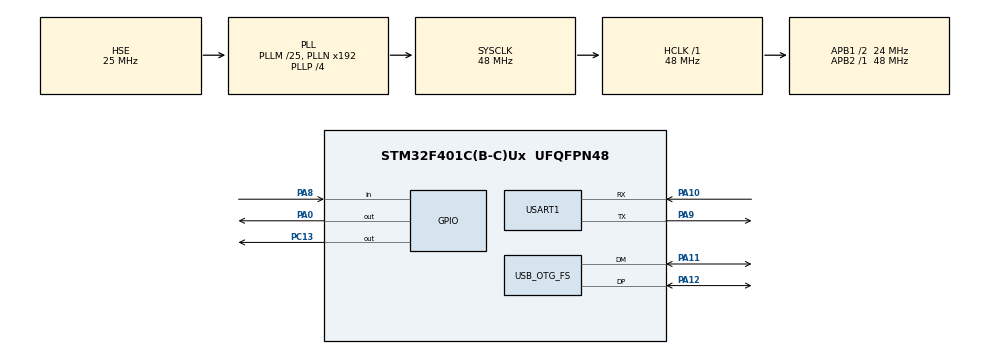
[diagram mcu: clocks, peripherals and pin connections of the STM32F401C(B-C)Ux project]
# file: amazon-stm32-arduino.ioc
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Mcu.Family=STM32F4
Mcu.Name=STM32F401C(B-C)Ux
Mcu.Package=UFQFPN48
NVIC.OTG_FS_IRQn=true\:0\:0\:false\:false\:true\:false\:true\:true
NVIC.PriorityGroup=NVIC_PRIORITYGROUP_4
PA0-WKUP.Signal=GPIO_Output
PA10.Mode=Asynchronous
PA10.Signal=USART1_RX
PA11.Mode=Device_Only
PA11.Signal=USB_OTG_FS_DM
PA12.Mode=Device_Only
PA12.Signal=USB_OTG_FS_DP
PA8.GPIO_PuPd=GPIO_PULLUP
PA8.Signal=GPIO_Input
PA9.Mode=Asynchronous
PA9.Signal=USART1_TX
PC13-ANTI_TAMP.Signal=GPIO_Output
PH0\ -\ OSC_IN.Mode=HSE-External-Oscillator
PH0\ -\ OSC_IN.Signal=RCC_OSC_IN
PH1\ -\ OSC_OUT.Mode=HSE-External-Oscillator
PH1\ -\ OSC_OUT.Signal=RCC_OSC_OUT
ProjectManager.HeapSize=0x200
ProjectManager.StackSize=0x400
ProjectManager.TargetToolchain=STM32CubeIDE
RCC.48MHZClocksFreq_Value=48000000
RCC.AHBFreq_Value=48000000
RCC.APB1CLKDivider=RCC_HCLK_DIV2
RCC.APB1Freq_Value=24000000
RCC.APB1TimFreq_Value=48000000
RCC.APB2Freq_Value=48000000
RCC.APB2TimFreq_Value=48000000
RCC.CortexFreq_Value=48000000
RCC.HCLKFreq_Value=48000000
RCC.HSE_VALUE=25000000
RCC.HSI_VALUE=16000000
RCC.LSE_VALUE=32768
RCC.PLLM=25
RCC.PLLP=RCC_PLLP_DIV4
RCC.SYSCLKFreq_VALUE=48000000
RCC.SYSCLKSource=RCC_SYSCLKSOURCE_PLLCLK
RCC.VCOOutputFreq_Value=192000000
USART1.VirtualMode=VM_ASYNC
USB_DEVICE.CLASS_NAME_FS=CDC
USB_DEVICE.VirtualMode=Cdc
USB_DEVICE.VirtualModeFS=Cdc_FS
USB_OTG_FS.VirtualMode=Device_Only
VP_USB_DEVICE_VS_USB_DEVICE_CDC_FS.Mode=CDC_FS
board=custom

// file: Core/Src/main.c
/* USER CODE BEGIN Header */
/**
 ******************************************************************************
 * @file           : main.c
 * @brief          : Main program body
 ******************************************************************************
 * @attention
 *
 * <h2><center>&copy; Copyright (c) 2022 STMicroelectronics.
 * All rights reserved.</center></h2>
 *
 * This software component is licensed by ST under BSD 3-Clause license,
 * the "License"; You may not use this file except in compliance with the
 * License. You may obtain a copy of the License at:
 *                        opensource.org/licenses/BSD-3-Clause
 *
 ******************************************************************************
 */
/* USER CODE END Header */
#include "main.h"
#include "usart.h"
#include "usb_device.h"
#include "gpio.h"

/* USER CODE BEGIN Includes */
#include <stdbool.h>
/* USER CODE END Includes */

void SystemClock_Config(void);

/* USER CODE BEGIN 0 */

// Defined deep within STM32 driver code, but we yank it out here
extern USBD_HandleTypeDef hUsbDeviceFS;

#include "usbd_cdc_if.h"

// Overwrite _write so printf prints to USB
int _write(int file, char *ptr, int len) {
  // Check here to make sure that USB things are actually set up
  if (hUsbDeviceFS.dev_state != USBD_STATE_CONFIGURED) return 0;

  // Try to send -- CDC_Transmit_FS is what actually sends our data
  if (USBD_OK == CDC_Transmit_FS((uint8_t *)ptr, len)) return len;

  // Failure, report sending zero bytes
  return 0;
}
/* USER CODE END 0 */

int main(void)
{

  /* MCU Configuration--------------------------------------------------------*/

  /* Reset of all peripherals, Initializes the Flash interface and the Systick. */
  HAL_Init();

  /* Configure the system clock */
  SystemClock_Config();

  /* Initialize all configured peripherals */
  MX_GPIO_Init();
  MX_USB_DEVICE_Init();
  MX_USART1_UART_Init();

  /* Infinite loop */
  /* USER CODE BEGIN WHILE */
  while (1) {
    //    bool buttonState = HAL_GPIO_ReadPin(GPIOC, GPIO_PIN_4);
    //    if (buttonState) {
    //      HAL_GPIO_WritePin(GPIOA, GPIO_PIN_1, GPIO_PIN_SET);
    //    } else {
    //      HAL_GPIO_WritePin(GPIOA, GPIO_PIN_1, GPIO_PIN_RESET);
    //    }

    // We want to turn pin PA0 (same as on breadboard) "ON"
    // to turn LED on
    // On == Set, Off = Reset
    HAL_GPIO_WritePin(GPIOC, GPIO_PIN_13, GPIO_PIN_SET);

    // Wait half a second (or 500ms
    HAL_Delay(500);

    // Turn LED back off
    HAL_GPIO_WritePin(GPIOC, GPIO_PIN_13, GPIO_PIN_RESET);

    // And wait a bit
    HAL_Delay(500);

    /* USER CODE END WHILE */

  }
}

void SystemClock_Config(void)
{
  RCC_OscInitTypeDef RCC_OscInitStruct = {0};
  RCC_ClkInitTypeDef RCC_ClkInitStruct = {0};

  /** Configure the main internal regulator output voltage
  */
  __HAL_RCC_PWR_CLK_ENABLE();
  __HAL_PWR_VOLTAGESCALING_CONFIG(PWR_REGULATOR_VOLTAGE_SCALE2);
  /** Initializes the RCC Oscillators according to the specified parameters
  * in the RCC_OscInitTypeDef structure.
  */
  RCC_OscInitStruct.OscillatorType = RCC_OSCILLATORTYPE_HSE;
  RCC_OscInitStruct.HSEState = RCC_HSE_ON;
  RCC_OscInitStruct.PLL.PLLState = RCC_PLL_ON;
  RCC_OscInitStruct.PLL.PLLSource = RCC_PLLSOURCE_HSE;
  RCC_OscInitStruct.PLL.PLLM = 25;
  RCC_OscInitStruct.PLL.PLLN = 192;
  RCC_OscInitStruct.PLL.PLLP = RCC_PLLP_DIV4;
  RCC_OscInitStruct.PLL.PLLQ = 4;
  if (HAL_RCC_OscConfig(&RCC_OscInitStruct) != HAL_OK)
  {
    Error_Handler();
  }
  /** Initializes the CPU, AHB and APB buses clocks
  */
  RCC_ClkInitStruct.ClockType = RCC_CLOCKTYPE_HCLK|RCC_CLOCKTYPE_SYSCLK
                              |RCC_CLOCKTYPE_PCLK1|RCC_CLOCKTYPE_PCLK2;
  RCC_ClkInitStruct.SYSCLKSource = RCC_SYSCLKSOURCE_PLLCLK;
  RCC_ClkInitStruct.AHBCLKDivider = RCC_SYSCLK_DIV1;
  RCC_ClkInitStruct.APB1CLKDivider = RCC_HCLK_DIV2;
  RCC_ClkInitStruct.APB2CLKDivider = RCC_HCLK_DIV1;

  if (HAL_RCC_ClockConfig(&RCC_ClkInitStruct, FLASH_LATENCY_1) != HAL_OK)
  {
    Error_Handler();
  }
}

void Error_Handler(void)
{
  __disable_irq();
  while (1) {
  }
}

#ifdef  USE_FULL_ASSERT
/**
  * @brief  Reports the name of the source file and the source line number
  *         where the assert_param error has occurred.
  * @param  file: pointer to the source file name
  * @param  line: assert_param error line source number
  * @retval None
  */
void assert_failed(uint8_t *file, uint32_t line)
{
  /* USER CODE BEGIN 6 */
  /* User can add his own implementation to report the file name and line
     number, ex: printf("Wrong parameters value: file %s on line %d\r\n", file,
     line) */
  /* USER CODE END 6 */
}
#endif /* USE_FULL_ASSERT */

/************************ (C) COPYRIGHT STMicroelectronics *****END OF FILE****/
